VERSION ""

NS_ :

BS_:

BU_: DEBUG BMS DCM FSM PDM DIM GSM INVR INVL CAN_DBG

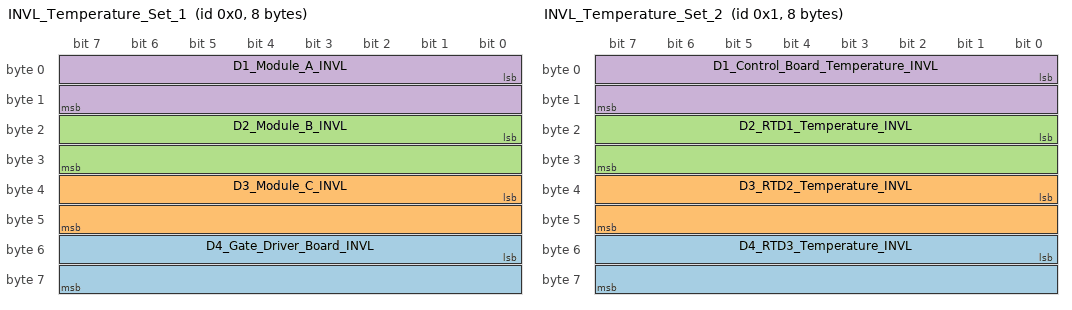
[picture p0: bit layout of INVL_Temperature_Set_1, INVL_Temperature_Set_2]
BO_ 0 INVL_Temperature_Set_1: 8 INVL
SG_ D4_Gate_Driver_Board_INVL : 48|16@1- (0.1,0) [-3276.8|3276.7] "degC" DEBUG
SG_ D3_Module_C_INVL : 32|16@1- (0.1,0) [-3276.8|3276.7] "degC" DEBUG
SG_ D2_Module_B_INVL : 16|16@1- (0.1,0) [-3276.8|3276.7] "degC" DEBUG
SG_ D1_Module_A_INVL : 0|16@1- (0.1,0) [-3276.8|3276.7] "degC" DEBUG

BO_ 1 INVL_Temperature_Set_2: 8 INVL
SG_ D4_RTD3_Temperature_INVL : 48|16@1- (0.1,0) [-3276.8|3276.7] "degC" DEBUG
SG_ D3_RTD2_Temperature_INVL : 32|16@1- (0.1,0) [-3276.8|3276.7] "degC" DEBUG
SG_ D2_RTD1_Temperature_INVL : 16|16@1- (0.1,0) [-3276.8|3276.7] "degC" DEBUG
SG_ D1_Control_Board_Temperature_INVL : 0|16@1- (0.1,0) [-3276.8|3276.7] "degC" DEBUG

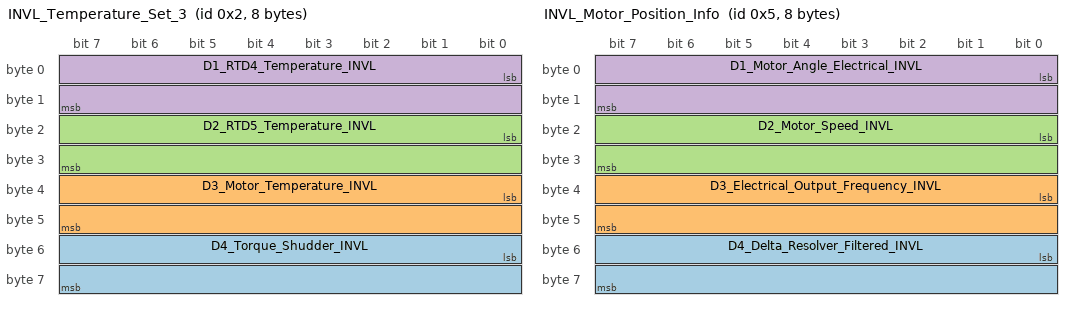
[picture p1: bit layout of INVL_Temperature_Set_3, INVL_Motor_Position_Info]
BO_ 2 INVL_Temperature_Set_3: 8 INVL
SG_ D4_Torque_Shudder_INVL : 48|16@1- (0.1,0) [-3276.8|3276.7] "Nm" DEBUG
SG_ D3_Motor_Temperature_INVL : 32|16@1- (0.1,0) [-3276.8|3276.7] "degC" DEBUG
SG_ D2_RTD5_Temperature_INVL : 16|16@1- (0.1,0) [-3276.8|3276.7] "degC" DEBUG
SG_ D1_RTD4_Temperature_INVL : 0|16@1- (0.1,0) [-3276.8|3276.7] "degC" DEBUG

BO_ 5 INVL_Motor_Position_Info: 8 INVL
SG_ D4_Delta_Resolver_Filtered_INVL : 48|16@1- (0.1,0) [-3276.8|3276.7] "deg" DEBUG
SG_ D3_Electrical_Output_Frequency_INVL : 32|16@1- (0.1,0) [-3276.8|3276.7] "hz" DEBUG
SG_ D2_Motor_Speed_INVL : 16|16@1- (1,0) [-32768|32767] "rpm" DCM
SG_ D1_Motor_Angle_Electrical_INVL : 0|16@1+ (0.1,0) [0|6553.5] "deg" DEBUG

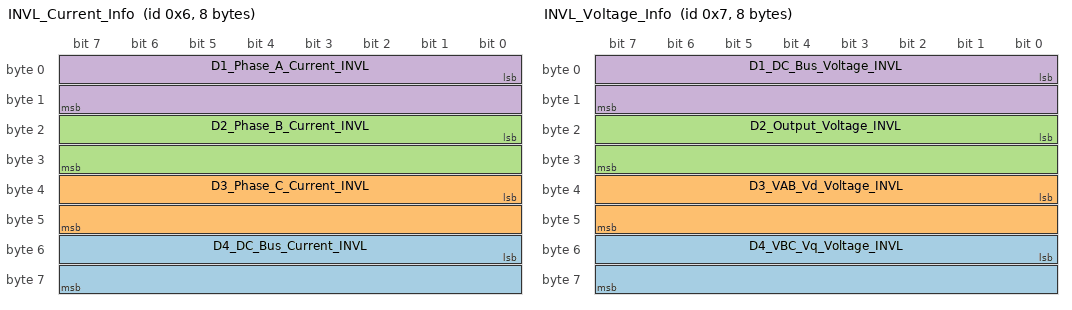
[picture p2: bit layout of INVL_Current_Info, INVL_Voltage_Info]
BO_ 6 INVL_Current_Info: 8 INVL
SG_ D4_DC_Bus_Current_INVL : 48|16@1- (0.1,0) [-3276.8|3276.7] "A" DEBUG
SG_ D3_Phase_C_Current_INVL : 32|16@1- (0.1,0) [-3276.8|3276.7] "A" DEBUG
SG_ D2_Phase_B_Current_INVL : 16|16@1- (0.1,0) [-3276.8|3276.7] "A" DEBUG
SG_ D1_Phase_A_Current_INVL : 0|16@1- (0.1,0) [-3276.8|3276.7] "A" DEBUG

BO_ 7 INVL_Voltage_Info: 8 INVL
SG_ D4_VBC_Vq_Voltage_INVL : 48|16@1- (0.1,0) [-3276.8|3276.7] "V" DEBUG
SG_ D3_VAB_Vd_Voltage_INVL : 32|16@1- (0.1,0) [-3276.8|3276.7] "V" DEBUG
SG_ D2_Output_Voltage_INVL : 16|16@1- (0.1,0) [-3276.8|3276.7] "V" DEBUG
SG_ D1_DC_Bus_Voltage_INVL : 0|16@1- (0.1,0) [-3276.8|3276.7] "V" DEBUG

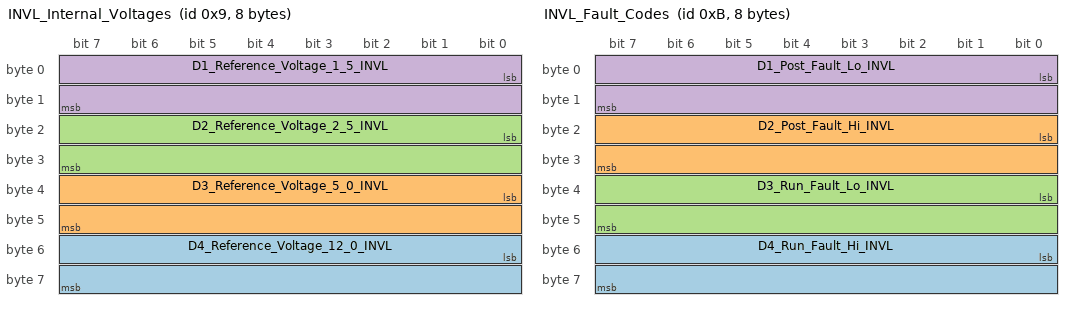
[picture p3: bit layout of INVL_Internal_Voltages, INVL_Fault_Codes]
BO_ 9 INVL_Internal_Voltages: 8 INVL
SG_ D4_Reference_Voltage_12_0_INVL : 48|16@1- (0.01,0) [-327.68|327.67] "V" DEBUG
SG_ D3_Reference_Voltage_5_0_INVL : 32|16@1- (0.01,0) [-327.68|327.67] "V" DEBUG
SG_ D2_Reference_Voltage_2_5_INVL : 16|16@1- (0.01,0) [-327.68|327.67] "V" DEBUG
SG_ D1_Reference_Voltage_1_5_INVL : 0|16@1- (0.01,0) [-327.68|327.67] "V" DEBUG

BO_ 10 INVL_Internal_States: 8 INVL
SG_ D7_Direction_Command_INVL : 56|1@1+ (1,0) [0|1] "" DEBUG
SG_ D6_Inverter_Enable_State_INVL : 48|1@1+ (1,0) [0|1] "" DEBUG
SG_ D3_Relay_3_Status_INVL : 26|1@1+ (1,0) [0|1] "" DEBUG
SG_ D3_Relay_4_Status_INVL : 27|1@1+ (1,0) [0|1] "" DEBUG
SG_ D3_Relay_2_Status_INVL : 25|1@1+ (1,0) [0|1] "" DEBUG
SG_ D4_Inverter_Run_Mode_INVL : 32|1@1+ (1,0) [0|1] "" DEBUG
SG_ D5_Inverter_Command_Mode_INVL : 40|1@1+ (1,0) [0|1] "" DEBUG
SG_ D3_Relay_1_Status_INVL : 24|1@1+ (1,0) [0|1] "" DEBUG
SG_ D2_Inverter_State_INVL : 16|8@1+ (1,0) [0|255] "" DEBUG
SG_ D1_VSM_State_INVL : 0|8@1+ (1,0) [0|15] "" DCM
SG_ D6_Inverter_Enable_Lockout_INVL : 55|1@1+ (1,0) [0|1] "" DEBUG
SG_ D4_Inverter_Discharge_State_INVL : 37|3@1+ (1,0) [0|7] "" DEBUG
SG_ D3_Relay_5_Status_INVL : 28|1@1+ (1,0) [0|1] "" DEBUG
SG_ D3_Relay_6_Status_INVL : 29|1@1+ (1,0) [0|1] "" DEBUG
SG_ D7_BMS_Active_INVL : 57|1@1+ (1,0) [0|1] "" DEBUG
SG_ D7_BMS_Torque_Limiting_INVL : 58|1@1+ (1,0) [0|1] "" DEBUG
SG_ D7_Max_Speed_Limiting_INVL : 59|1@1+ (1,0) [0|1] "" DEBUG
SG_ D7_Low_Speed_Limiting_INVL : 61|1@1+ (1,0) [0|1] "" DEBUG
SG_ D5_Rolling_Counter_INVL : 44|4@1+ (1,0) [0|15] "" DEBUG
SG_ D1_PWM_Frequency_INVL : 8|8@1+ (1,0) [0|255] "kHz" DEBUG
SG_ D6_Start_Mode_Active_INVL : 54|1@1+ (1,0) [0|1] "" DEBUG

BO_ 11 INVL_Fault_Codes: 8 INVL
SG_ D4_Run_Fault_Hi_INVL : 48|16@1+ (1,0) [0|65535] "" DEBUG
SG_ D2_Post_Fault_Hi_INVL : 16|16@1+ (1,0) [0|65535] "" DEBUG
SG_ D3_Run_Fault_Lo_INVL : 32|16@1+ (1,0) [0|65535] "" DEBUG
SG_ D1_Post_Fault_Lo_INVL : 0|16@1+ (1,0) [0|65535] "" DEBUG

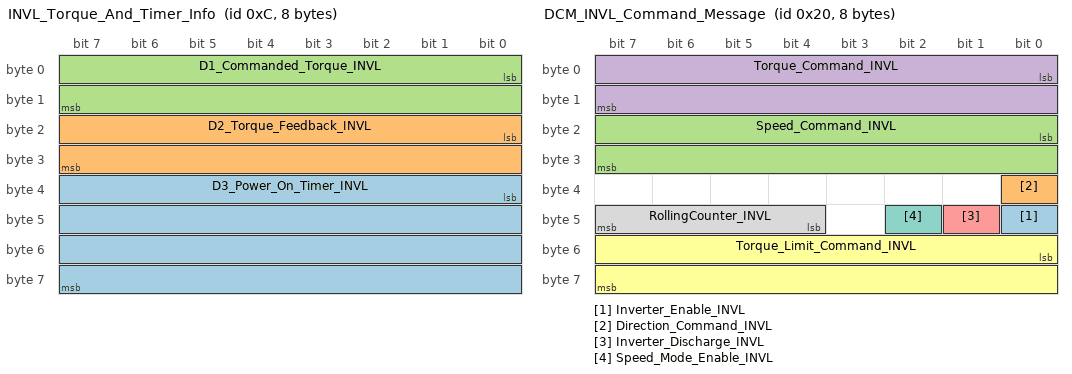
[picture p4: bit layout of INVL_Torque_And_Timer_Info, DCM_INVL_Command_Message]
BO_ 12 INVL_Torque_And_Timer_Info: 8 INVL
SG_ D3_Power_On_Timer_INVL : 32|32@1+ (0.003,0) [0|12884800] "Sec" DEBUG
SG_ D2_Torque_Feedback_INVL : 16|16@1- (0.1,0) [-3276.8|3276.7] "Nm" DEBUG
SG_ D1_Commanded_Torque_INVL : 0|16@1- (0.1,0) [-3276.8|3276.7] "Nm" DEBUG

BO_ 32 DCM_INVL_Command_Message: 8 DCM
SG_ Inverter_Enable_INVL : 40|1@1+ (1,0) [0|1] "Bit" INVL
SG_ Direction_Command_INVL : 32|1@1+ (1,0) [0|1] "Bit" INVL
SG_ Speed_Command_INVL : 16|16@1- (1,0) [-32768|32767] "rpm" INVL
SG_ Torque_Command_INVL : 0|16@1- (0.1,0) [-3276.8|3276.7] "Nm" INVL,FSM
SG_ Inverter_Discharge_INVL : 41|1@1+ (1,0) [0|1] "Bit" INVL
SG_ Torque_Limit_Command_INVL : 48|16@1- (0.1,0) [-3276.8|3276.7] "Nm" INVL
SG_ Speed_Mode_Enable_INVL : 42|1@1+ (1,0) [0|1] "Bit" INVL
SG_ RollingCounter_INVL : 44|4@1+ (1,0) [0|15] "Bits" INVL

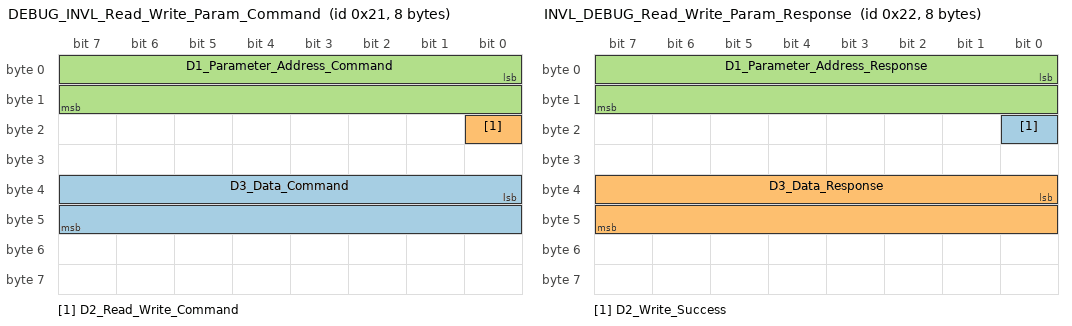
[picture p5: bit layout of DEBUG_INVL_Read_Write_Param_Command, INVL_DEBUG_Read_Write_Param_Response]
BO_ 33 DEBUG_INVL_Read_Write_Param_Command: 8 DEBUG
SG_ D3_Data_Command : 32|16@1- (1,0) [-32768|32767] "" INVL
SG_ D2_Read_Write_Command : 16|1@1+ (1,0) [0|1] "" INVL
SG_ D1_Parameter_Address_Command : 0|16@1+ (1,0) [0|65535] "" INVL

BO_ 34 INVL_DEBUG_Read_Write_Param_Response: 8 INVL
SG_ D2_Write_Success : 16|1@1+ (1,0) [0|1] "" DEBUG
SG_ D3_Data_Response : 32|16@1- (1,0) [-32768|32767] "" DEBUG
SG_ D1_Parameter_Address_Response : 0|16@1+ (1,0) [0|65535] "" DEBUG

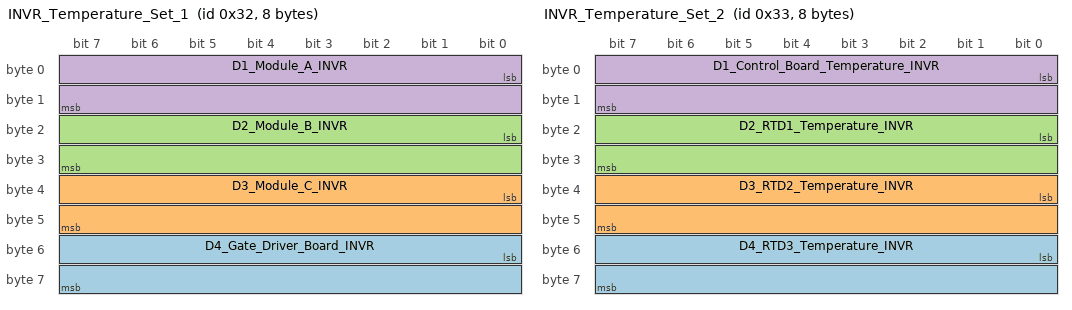
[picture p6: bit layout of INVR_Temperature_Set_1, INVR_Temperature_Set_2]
BO_ 50 INVR_Temperature_Set_1: 8 INVR
SG_ D4_Gate_Driver_Board_INVR : 48|16@1- (0.1,0) [-3276.8|3276.7] "degC" DEBUG
SG_ D3_Module_C_INVR : 32|16@1- (0.1,0) [-3276.8|3276.7] "degC" DEBUG
SG_ D2_Module_B_INVR : 16|16@1- (0.1,0) [-3276.8|3276.7] "degC" DEBUG
SG_ D1_Module_A_INVR : 0|16@1- (0.1,0) [-3276.8|3276.7] "degC" DEBUG

BO_ 51 INVR_Temperature_Set_2: 8 INVR
SG_ D4_RTD3_Temperature_INVR : 48|16@1- (0.1,0) [-3276.8|3276.7] "degC" DEBUG
SG_ D3_RTD2_Temperature_INVR : 32|16@1- (0.1,0) [-3276.8|3276.7] "degC" DEBUG
SG_ D2_RTD1_Temperature_INVR : 16|16@1- (0.1,0) [-3276.8|3276.7] "degC" DEBUG
SG_ D1_Control_Board_Temperature_INVR : 0|16@1- (0.1,0) [-3276.8|3276.7] "degC" DEBUG

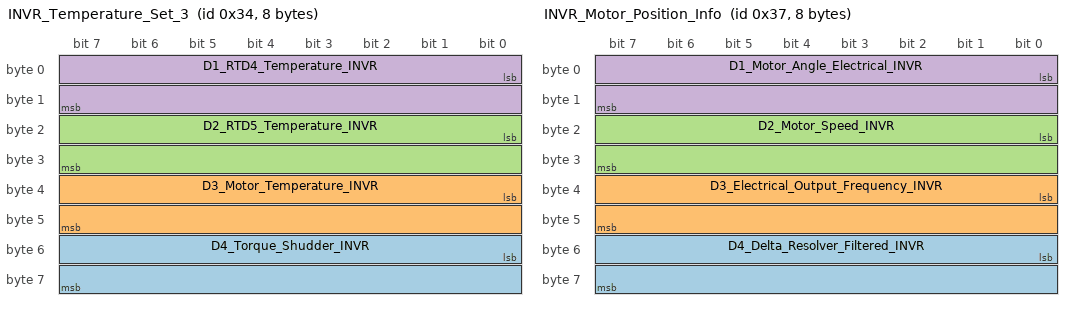
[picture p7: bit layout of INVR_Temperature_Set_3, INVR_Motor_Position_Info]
BO_ 52 INVR_Temperature_Set_3: 8 INVR
SG_ D4_Torque_Shudder_INVR : 48|16@1- (0.1,0) [-3276.8|3276.7] "Nm" DEBUG
SG_ D3_Motor_Temperature_INVR : 32|16@1- (0.1,0) [-3276.8|3276.7] "degC" DEBUG
SG_ D2_RTD5_Temperature_INVR : 16|16@1- (0.1,0) [-3276.8|3276.7] "degC" DEBUG
SG_ D1_RTD4_Temperature_INVR : 0|16@1- (0.1,0) [-3276.8|3276.7] "degC" DEBUG

BO_ 55 INVR_Motor_Position_Info: 8 INVR
SG_ D4_Delta_Resolver_Filtered_INVR : 48|16@1- (0.1,0) [-3276.8|3276.7] "deg" DEBUG
SG_ D3_Electrical_Output_Frequency_INVR : 32|16@1- (0.1,0) [-3276.8|3276.7] "hz" DEBUG
SG_ D2_Motor_Speed_INVR : 16|16@1- (1,0) [-32768|32767] "rpm" DCM
SG_ D1_Motor_Angle_Electrical_INVR : 0|16@1+ (0.1,0) [0|6553.5] "deg" DEBUG

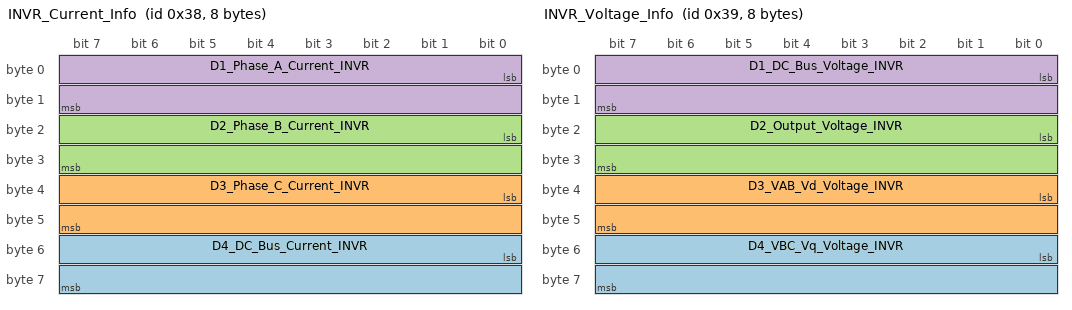
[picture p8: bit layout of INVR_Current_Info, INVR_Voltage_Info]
BO_ 56 INVR_Current_Info: 8 INVR
SG_ D4_DC_Bus_Current_INVR : 48|16@1- (0.1,0) [-3276.8|3276.7] "A" DEBUG
SG_ D3_Phase_C_Current_INVR : 32|16@1- (0.1,0) [-3276.8|3276.7] "A" DEBUG
SG_ D2_Phase_B_Current_INVR : 16|16@1- (0.1,0) [-3276.8|3276.7] "A" DEBUG
SG_ D1_Phase_A_Current_INVR : 0|16@1- (0.1,0) [-3276.8|3276.7] "A" DEBUG

BO_ 57 INVR_Voltage_Info: 8 INVR
SG_ D4_VBC_Vq_Voltage_INVR : 48|16@1- (0.1,0) [-3276.8|3276.7] "V" DEBUG
SG_ D3_VAB_Vd_Voltage_INVR : 32|16@1- (0.1,0) [-3276.8|3276.7] "V" DEBUG
SG_ D2_Output_Voltage_INVR : 16|16@1- (0.1,0) [-3276.8|3276.7] "V" DEBUG
SG_ D1_DC_Bus_Voltage_INVR : 0|16@1- (0.1,0) [-3276.8|3276.7] "V" DEBUG

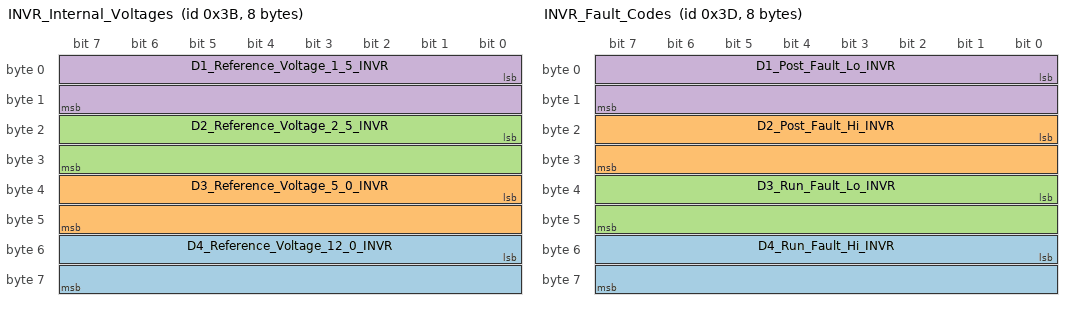
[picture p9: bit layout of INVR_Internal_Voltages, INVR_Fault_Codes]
BO_ 59 INVR_Internal_Voltages: 8 INVR
SG_ D4_Reference_Voltage_12_0_INVR : 48|16@1- (0.01,0) [-327.68|327.67] "V" DEBUG
SG_ D3_Reference_Voltage_5_0_INVR : 32|16@1- (0.01,0) [-327.68|327.67] "V" DEBUG
SG_ D2_Reference_Voltage_2_5_INVR : 16|16@1- (0.01,0) [-327.68|327.67] "V" DEBUG
SG_ D1_Reference_Voltage_1_5_INVR : 0|16@1- (0.01,0) [-327.68|327.67] "V" DEBUG

BO_ 60 INVR_Internal_States: 8 INVR
SG_ D7_Direction_Command_INVR : 56|1@1+ (1,0) [0|1] "" DEBUG
SG_ D6_Inverter_Enable_State_INVR : 48|1@1+ (1,0) [0|1] "" DEBUG
SG_ D3_Relay_3_Status_INVR : 26|1@1+ (1,0) [0|1] "" DEBUG
SG_ D3_Relay_4_Status_INVR : 27|1@1+ (1,0) [0|1] "" DEBUG
SG_ D3_Relay_2_Status_INVR : 25|1@1+ (1,0) [0|1] "" DEBUG
SG_ D4_Inverter_Run_Mode_INVR : 32|1@1+ (1,0) [0|1] "" DEBUG
SG_ D5_Inverter_Command_Mode_INVR : 40|1@1+ (1,0) [0|1] "" DEBUG
SG_ D3_Relay_1_Status_INVR : 24|1@1+ (1,0) [0|1] "" DEBUG
SG_ D2_Inverter_State_INVR : 16|8@1+ (1,0) [0|255] "" DEBUG
SG_ D1_VSM_State_INVR : 0|8@1+ (1,0) [0|15] "" DCM
SG_ D6_Inverter_Enable_Lockout_INVR : 55|1@1+ (1,0) [0|1] "" DEBUG
SG_ D4_Inverter_Discharge_State_INVR : 37|3@1+ (1,0) [0|7] "" DEBUG
SG_ D3_Relay_5_Status_INVR : 28|1@1+ (1,0) [0|1] "" DEBUG
SG_ D3_Relay_6_Status_INVR : 29|1@1+ (1,0) [0|1] "" DEBUG
SG_ D7_BMS_Active_INVR : 57|1@1+ (1,0) [0|1] "" DEBUG
SG_ D7_BMS_Torque_Limiting_INVR : 58|1@1+ (1,0) [0|1] "" DEBUG
SG_ D7_Max_Speed_Limiting_INVR : 59|1@1+ (1,0) [0|1] "" DEBUG
SG_ D7_Low_Speed_Limiting_INVR : 61|1@1+ (1,0) [0|1] "" DEBUG
SG_ D5_Rolling_Counter_INVR : 44|4@1+ (1,0) [0|15] "" DEBUG
SG_ D1_PWM_Frequency_INVR : 8|8@1+ (1,0) [0|255] "kHz" DEBUG
SG_ D6_Start_Mode_Active_INVR : 54|1@1+ (1,0) [0|1] "" DEBUG

BO_ 61 INVR_Fault_Codes: 8 INVR
SG_ D4_Run_Fault_Hi_INVR : 48|16@1+ (1,0) [0|65535] "" DEBUG
SG_ D2_Post_Fault_Hi_INVR : 16|16@1+ (1,0) [0|65535] "" DEBUG
SG_ D3_Run_Fault_Lo_INVR : 32|16@1+ (1,0) [0|65535] "" DEBUG
SG_ D1_Post_Fault_Lo_INVR : 0|16@1+ (1,0) [0|65535] "" DEBUG

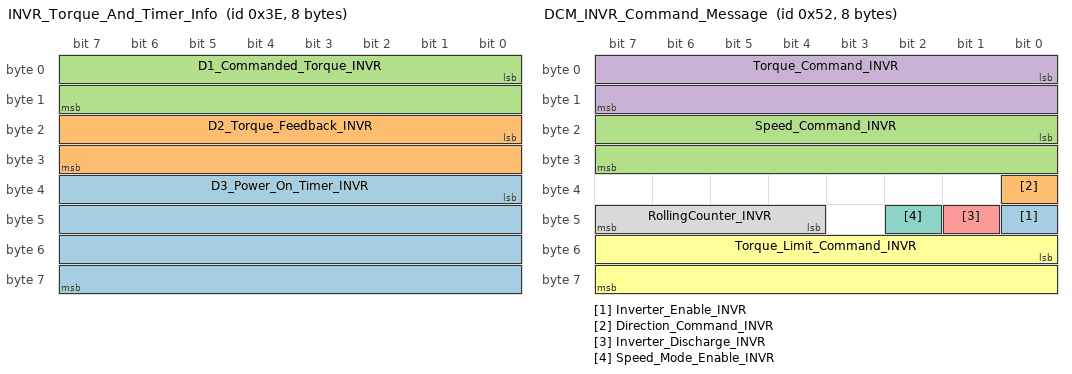
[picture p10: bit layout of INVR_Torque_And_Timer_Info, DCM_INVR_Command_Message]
BO_ 62 INVR_Torque_And_Timer_Info: 8 INVR
SG_ D3_Power_On_Timer_INVR : 32|32@1+ (0.003,0) [0|12884800] "Sec" DEBUG
SG_ D2_Torque_Feedback_INVR : 16|16@1- (0.1,0) [-3276.8|3276.7] "Nm" DEBUG
SG_ D1_Commanded_Torque_INVR : 0|16@1- (0.1,0) [-3276.8|3276.7] "Nm" DEBUG

BO_ 82 DCM_INVR_Command_Message: 8 DCM
SG_ Inverter_Enable_INVR : 40|1@1+ (1,0) [0|1] "Bit" INVR
SG_ Direction_Command_INVR : 32|1@1+ (1,0) [0|1] "Bit" INVR
SG_ Speed_Command_INVR : 16|16@1- (1,0) [-32768|32767] "rpm" INVR
SG_ Torque_Command_INVR : 0|16@1- (0.1,0) [-3276.8|3276.7] "Nm" INVR,FSM
SG_ Inverter_Discharge_INVR : 41|1@1+ (1,0) [0|1] "Bit" INVR
SG_ Torque_Limit_Command_INVR : 48|16@1- (0.1,0) [-3276.8|3276.7] "Nm" INVR
SG_ Speed_Mode_Enable_INVR : 42|1@1+ (1,0) [0|1] "Bit" INVR
SG_ RollingCounter_INVR : 44|4@1+ (1,0) [0|15] "Bits" INVR

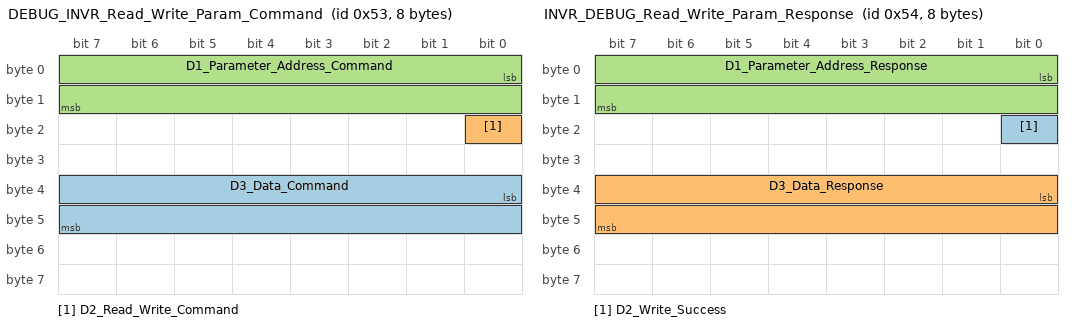
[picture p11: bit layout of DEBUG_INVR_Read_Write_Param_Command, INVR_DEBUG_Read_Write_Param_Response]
BO_ 83 DEBUG_INVR_Read_Write_Param_Command: 8 DEBUG
SG_ D3_Data_Command : 32|16@1- (1,0) [-32768|32767] "" INVR
SG_ D2_Read_Write_Command : 16|1@1+ (1,0) [0|1] "" INVR
SG_ D1_Parameter_Address_Command : 0|16@1+ (1,0) [0|65535] "" INVR

BO_ 84 INVR_DEBUG_Read_Write_Param_Response: 8 INVR
SG_ D2_Write_Success : 16|1@1+ (1,0) [0|1] "" DEBUG
SG_ D3_Data_Response : 32|16@1- (1,0) [-32768|32767] "" DEBUG
SG_ D1_Parameter_Address_Response : 0|16@1+ (1,0) [0|65535] "" DEBUG

BO_ 13 FSM_PEDAL_POSITION: 4 FSM
SG_ Mapped_Pedal_Percentage: 0|32@1+ (1,0) [0|100] "%" DCM

BO_ 90 FSM_Torque_Limiting : 4 FSM
SG_ FSM_Torque_Limit : 0|32@1+ (1,0) [0.0|150.0] "Nm" DCM

BO_ 100 BMS_VITALS: 1 BMS
SG_ HEARTBEAT : 0|1@1+ (1,0) [0|1] "" FSM,DCM,PDM,DIM,GSM

BO_ 101 BMS_CAN_FIFO_OVERFLOW: 8 BMS
SG_ tx_overflow_count : 0|32@1+ (1,0) [0|4294967295] "" DEBUG
SG_ rx_overflow_count : 32|32@1+ (1,0) [0|4294967295] "" DEBUG

BO_ 102 BMS_STARTUP: 0 BMS

BO_ 103 BMS_WATCHDOG_TIMEOUT : 8 BMS
SG_ TASK_NAME : 0|64@1+ (1,0) [0|0] "" DEBUG

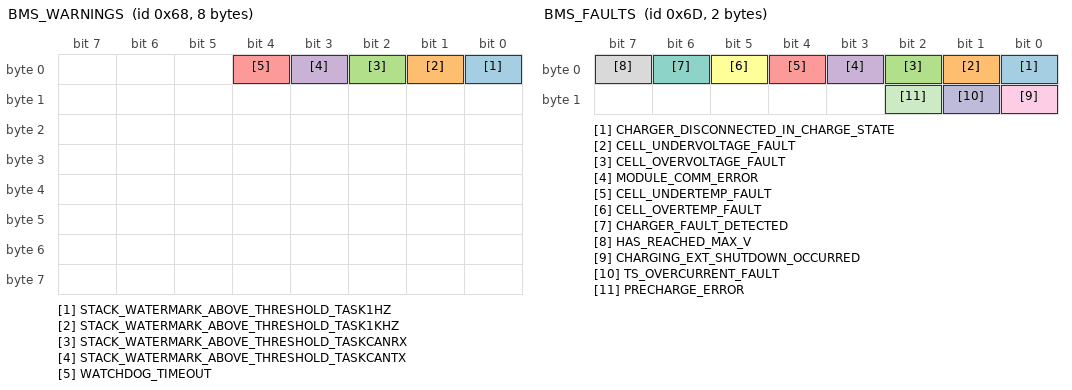
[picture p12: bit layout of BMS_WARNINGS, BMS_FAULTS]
BO_ 104 BMS_WARNINGS: 8 BMS
SG_ STACK_WATERMARK_ABOVE_THRESHOLD_TASK1HZ : 0|1@1+ (1,0) [0|1] "" DIM
SG_ STACK_WATERMARK_ABOVE_THRESHOLD_TASK1KHZ : 1|1@1+ (1,0) [0|1] "" DIM
SG_ STACK_WATERMARK_ABOVE_THRESHOLD_TASKCANRX : 2|1@1+ (1,0) [0|1] "" DIM
SG_ STACK_WATERMARK_ABOVE_THRESHOLD_TASKCANTX : 3|1@1+ (1,0) [0|1] "" DIM
SG_ WATCHDOG_TIMEOUT : 4|1@1+ (1,0) [0|1] "" DIM

BO_ 105 BMS_IMD: 8 BMS
SG_ Condition M : 0|3@1+ (1,0) [0|6] "" DEBUG
SG_ Seconds_Since_Power_On : 3|16@1+ (1,0) [0|255] "Seconds" DEBUG
SG_ Valid_Duty_Cycle : 19|1@1+ (1,0) [0|1] "" DEBUG
SG_ Insulation_Measurement_DCP_10Hz m1 : 20|16@1+ (1,0) [0|65535] "kOhm" DEBUG
SG_ Insulation_Measurement_DCP_20Hz m2 : 20|16@1+ (1,0) [0|65535] "kOhm" DEBUG
SG_ Speed_Start_Status_30Hz m3 : 20|16@1+ (1,0) [0|65535] "" DEBUG
SG_ OK_HS : 36|1@1+ (1,0) [0|1] "" DIM

BO_ 106 BMS_IMD_PWM_OUTPUT : 8 BMS
SG_ Duty_Cycle : 0|32@1- (1,0) [0|1E2] "%" DEBUG
SG_ Frequency : 32|32@1- (1,0) [0|1E4] "Hz" DEBUG

BO_ 107 BMS_STATE_MACHINE : 1 BMS
SG_ State : 0|8@1+ (1,0) [0|255] "" DCM,DIM

BO_ 108 BMS_STATE_OF_CHARGE: 4 BMS
SG_ State_Of_Charge : 0|32@1- (1,0) [0|1E2] "%" DIM

BO_ 109 BMS_FAULTS: 2 BMS
SG_ CHARGER_DISCONNECTED_IN_CHARGE_STATE : 0|1@1+ (1,0) [0|1] "" DEBUG
SG_ CELL_UNDERVOLTAGE_FAULT : 1|1@1+ (1,0) [0|1] "" DEBUG
SG_ CELL_OVERVOLTAGE_FAULT : 2|1@1+ (1,0) [0|1] "" DEBUG
SG_ MODULE_COMM_ERROR: 3|1@1+ (1,0) [0|1] "" DEBUG
SG_ CELL_UNDERTEMP_FAULT: 4|1@1+ (1,0) [0|1] "" DEBUG
SG_ CELL_OVERTEMP_FAULT: 5|1@1+ (1,0) [0|1] "" DEBUG
SG_ CHARGER_FAULT_DETECTED : 6|1@1+ (1,0) [0|1] "" DEBUG
SG_ HAS_REACHED_MAX_V : 7|1@1+ (1,0) [0|1] "" DEBUG
SG_ CHARGING_EXT_SHUTDOWN_OCCURRED : 8|1@1+ (1,0) [0|1] "" DEBUG
SG_ TS_OVERCURRENT_FAULT : 9|1@1+ (1,0) [0|1] "" DEBUG
SG_ PRECHARGE_ERROR : 10|1@1+ (1,0) [0|1] "" DEBUG

BO_ 110 BMS_CHARGER: 1 BMS
SG_ Is_Connected : 0|1@1+ (1,0) [0|1] "" DEBUG
SG_ IS_CHARGING_COMPLETE : 1|1@1+ (1,0) [0|1] "" DEBUG

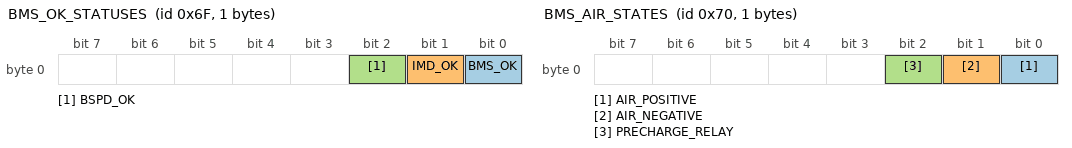
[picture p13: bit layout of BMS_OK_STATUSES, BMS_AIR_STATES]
BO_ 111 BMS_OK_STATUSES: 1 BMS
SG_ BMS_OK : 0|1@1+ (1,0) [0|1] "" DIM
SG_ IMD_OK : 1|1@1+ (1,0) [0|1] "" DIM
SG_ BSPD_OK : 2|1@1+ (1,0) [0|1] "" DIM

BO_ 112 BMS_AIR_STATES: 1 BMS
SG_ AIR_POSITIVE : 0|1@1+ (1,0) [0|1] "" FSM,DCM,PDM
SG_ AIR_NEGATIVE : 1|1@1+ (1,0) [0|1] "" FSM,DCM,PDM
SG_ PRECHARGE_RELAY: 2|1@1+ (1,0) [0|1] "" DEBUG

BO_ 113 BMS_MOTOR_SHUTDOWN_ERRORS: 8 BMS
SG_ DUMMY_MOTOR_SHUTDOWN : 0|1@1+ (1,0) [0|1] "" DCM

BO_ 114 BMS_CELL_TEMPERATURES: 8 BMS
SG_ MIN_CELL_TEMPERATURE: 0|32@1+ (1,0) [0|100] "degC" DEBUG
SG_ MAX_CELL_TEMPERATURE: 32|32@1+ (1,0) [0|100] "degC" DEBUG

BO_ 115 BMS_CELL_VOLTAGES: 8 BMS
SG_ MIN_CELL_VOLTAGE : 0|32@1+ (1,0) [0|5] "" DEBUG
SG_ MAX_CELL_VOLTAGE : 32|32@1+ (1,0) [0|5] "" DEBUG

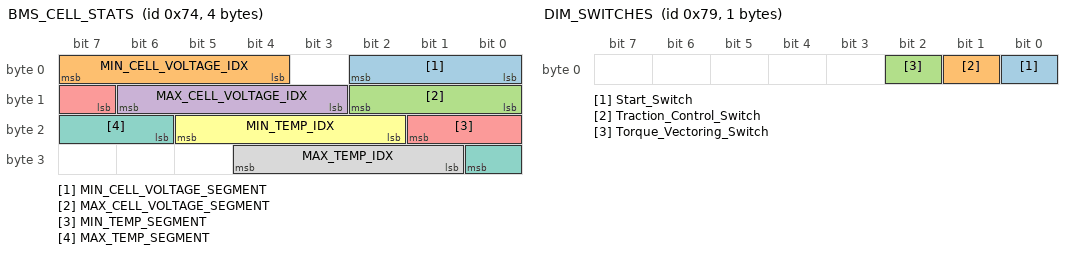
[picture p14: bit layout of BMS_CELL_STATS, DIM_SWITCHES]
BO_ 116 BMS_CELL_STATS: 4 BMS
SG_ MIN_CELL_VOLTAGE_SEGMENT : 0|3@1+ (1,0) [0|7] "" DEBUG
SG_ MIN_CELL_VOLTAGE_IDX : 4|4@1+ (1,0) [0|15] "" DEBUG
SG_ MAX_CELL_VOLTAGE_SEGMENT : 8|3@1+ (1,0) [0|7] "" DEBUG
SG_ MAX_CELL_VOLTAGE_IDX : 11|4@1+ (1,0) [0|7] "" DEBUG
SG_ MIN_TEMP_SEGMENT : 15|3@1+ (1,0) [0|7] "" DEBUG
SG_ MIN_TEMP_IDX : 18|4@1+ (1,0) [0|15] "" DEBUG
SG_ MAX_TEMP_SEGMENT : 22|3@1+ (1,0) [0|7] "" DEBUG
SG_ MAX_TEMP_IDX : 25|4@1+ (1,0) [0|7] "" DEBUG

BO_ 117 BMS_TRACTIVE_SYSTEM: 8 BMS
SG_ TS_VOLTAGE : 0|32@1+ (1,0) [0|600] "" DEBUG
SG_ TS_CURRENT : 32|32@1+ (1,0) [-300|300] "" DEBUG

BO_ 118 BMS_PACK_VOLTAGE: 4 BMS
SG_ PACK_VOLTAGE : 0|32@1+ (1,0) [0|600] "" DEBUG

BO_ 120 BMS_AVAILABLE_POWER: 4 BMS
SG_ AVAILABLE_POWER : 0|32@1+ (1,0) [0|100000] "W" DCM

BO_ 121 DIM_SWITCHES: 1 DIM
SG_ Start_Switch : 0|1@1+ (1,0) [0|1] "" DCM
SG_ Traction_Control_Switch : 1|1@1+ (1,0) [0|1] "" DCM
SG_ Torque_Vectoring_Switch : 2|1@1+ (1,0) [0|1] "" DCM

BO_ 151 FSM_APPS: 8 FSM
SG_ Papps_Mapped_Pedal_Percentage : 0|32@1+ (1,0) [0|100] "%" DEBUG
SG_ Sapps_Mapped_Pedal_Percentage : 32|32@1+ (1,0) [0|100] "%" DEBUG

BO_ 200 DCM_VITALS: 1 DCM
SG_ HEARTBEAT : 0|1@1+ (1,0) [0|1] "" BMS

BO_ 201 DCM_CAN_FIFO_OVERFLOW: 8 DCM
SG_ tx_overflow_count : 0|32@1+ (1,0) [0|4294967295] "" DEBUG
SG_ rx_overflow_count : 32|32@1+ (1,0) [0|4294967295] "" DEBUG

BO_ 202 DCM_STARTUP: 0 DCM

BO_ 203 DCM_WATCHDOG_TIMEOUT : 8 DCM
SG_ TASK_NAME : 0|64@1+ (1,0) [0|0] "" DEBUG

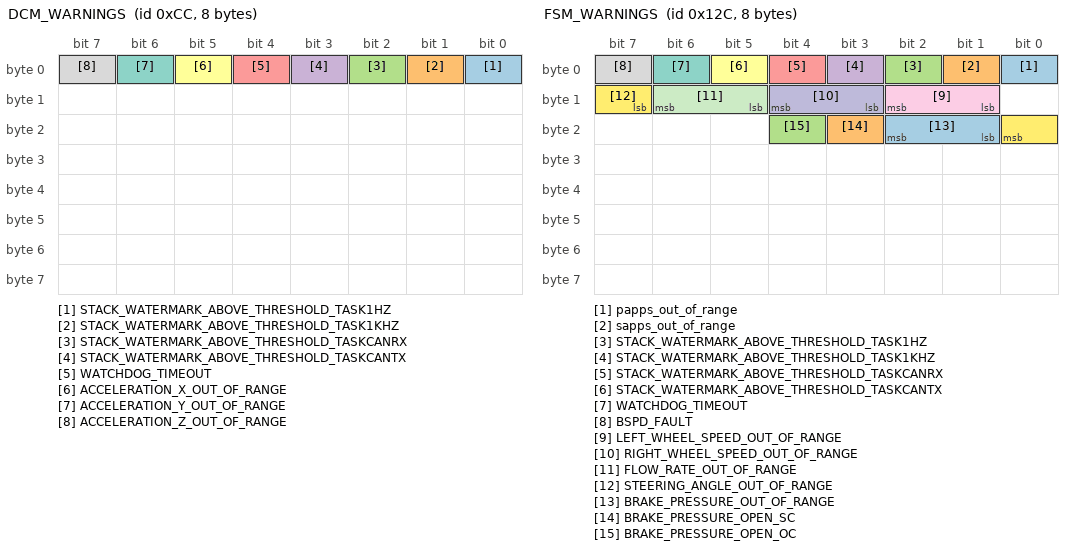
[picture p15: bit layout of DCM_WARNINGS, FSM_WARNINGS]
BO_ 204 DCM_WARNINGS: 8 DCM
SG_ STACK_WATERMARK_ABOVE_THRESHOLD_TASK1HZ : 0|1@1+ (1,0) [0|1] "" DEBUG
SG_ STACK_WATERMARK_ABOVE_THRESHOLD_TASK1KHZ : 1|1@1+ (1,0) [0|1] "" DEBUG
SG_ STACK_WATERMARK_ABOVE_THRESHOLD_TASKCANRX : 2|1@1+ (1,0) [0|1] "" DEBUG
SG_ STACK_WATERMARK_ABOVE_THRESHOLD_TASKCANTX : 3|1@1+ (1,0) [0|1] "" DEBUG
SG_ WATCHDOG_TIMEOUT : 4|1@1+ (1,0) [0|1] "" DEBUG
SG_ ACCELERATION_X_OUT_OF_RANGE : 5|1@1+ (1,0) [0|1] "" DEBUG
SG_ ACCELERATION_Y_OUT_OF_RANGE : 6|1@1+ (1,0) [0|1] "" DEBUG
SG_ ACCELERATION_Z_OUT_OF_RANGE : 7|1@1+ (1,0) [0|1] "" DEBUG

BO_ 205 DCM_STATE_MACHINE : 1 DCM
SG_ State : 0|8@1+ (1,0) [0|255] "" DEBUG

BO_ 206 DCM_TORQUE_REQUEST : 4 DCM
SG_ Torque_Request : 0|32@1+ (1,0) [-3.4E038|3.4E038] "" LOGGER

BO_ 207 DCM_AIR_SHUTDOWN_ERRORS: 1 DCM
SG_ MISSING_HEARTBEAT: 0|1@1+ (1,0) [0|1] "" DEBUG

BO_ 208 DCM_MOTOR_SHUTDOWN_ERRORS: 8 DCM
SG_ DUMMY_MOTOR_SHUTDOWN : 0|1@1+ (1,0) [0|1] "" DCM

BO_ 212 DCM_INVERTER_SWITCHES: 1 DCM
SG_ Right_Inverter_Switch : 0|1@1+ (1,0) [0|1] "" DEBUG
SG_ Left_Inverter_Switch : 1|1@1+ (1,0) [0|1] "" DEBUG

BO_ 300 FSM_WARNINGS: 8 FSM
SG_ papps_out_of_range : 0|1@1+ (1,0) [0|1] "" DEBUG
SG_ sapps_out_of_range : 1|1@1+ (1,0) [0|1] "" DEBUG
SG_ STACK_WATERMARK_ABOVE_THRESHOLD_TASK1HZ : 2|1@1+ (1,0) [0|1] "" DEBUG
SG_ STACK_WATERMARK_ABOVE_THRESHOLD_TASK1KHZ : 3|1@1+ (1,0) [0|1] "" DEBUG
SG_ STACK_WATERMARK_ABOVE_THRESHOLD_TASKCANRX : 4|1@1+ (1,0) [0|1] "" DEBUG
SG_ STACK_WATERMARK_ABOVE_THRESHOLD_TASKCANTX : 5|1@1+ (1,0) [0|1] "" DEBUG
SG_ WATCHDOG_TIMEOUT : 6|1@1+ (1,0) [0|1] "" DEBUG
SG_ BSPD_FAULT : 7|1@1+ (1,0) [0|1] "" DIM
SG_ LEFT_WHEEL_SPEED_OUT_OF_RANGE: 9|2@1+ (1,0) [0|2] "" DEBUG
SG_ RIGHT_WHEEL_SPEED_OUT_OF_RANGE: 11|2@1+ (1,0) [0|2] ""  DEBUG
SG_ FLOW_RATE_OUT_OF_RANGE: 13|2@1+ (1,0) [0|2] "" DEBUG
SG_ STEERING_ANGLE_OUT_OF_RANGE: 15|2@1+ (1,0) [0|2] "" DEBUG
SG_ BRAKE_PRESSURE_OUT_OF_RANGE: 17|2@1+ (1,0) [0|2] "" DEBUG
SG_ BRAKE_PRESSURE_OPEN_SC: 19|1@1+ (1,0) [0|1] "" DEBUG
SG_ BRAKE_PRESSURE_OPEN_OC: 20|1@1+ (1,0) [0|1] "" DEBUG

BO_ 301 FSM_VITALS: 1 FSM
SG_ HEARTBEAT : 0|1@1+ (1,0) [0|1] "" BMS

BO_ 302 FSM_CAN_FIFO_OVERFLOW: 8 FSM
SG_ tx_overflow_count : 0|32@1+ (1,0) [0|1] "" DEBUG
SG_ rx_overflow_count : 32|32@1+ (1,0) [0|1] "" DEBUG

BO_ 303 FSM_STARTUP: 0 FSM

BO_ 304 FSM_WATCHDOG_TIMEOUT : 8 FSM
SG_ TASK_NAME : 0|64@1+ (1,0) [0|0] "" DEBUG

BO_ 305 FSM_STATE_MACHINE : 1 FSM
SG_ State : 0|8@1+ (1,0) [0|255] "" DEBUG

BO_ 306 FSM_AIR_SHUTDOWN: 0 FSM

BO_ 307 FSM_FLOW_METER: 8 FSM
SG_ FLOW_RATE: 0|32@1+ (1,0) [0|100] "L/min" DEBUG

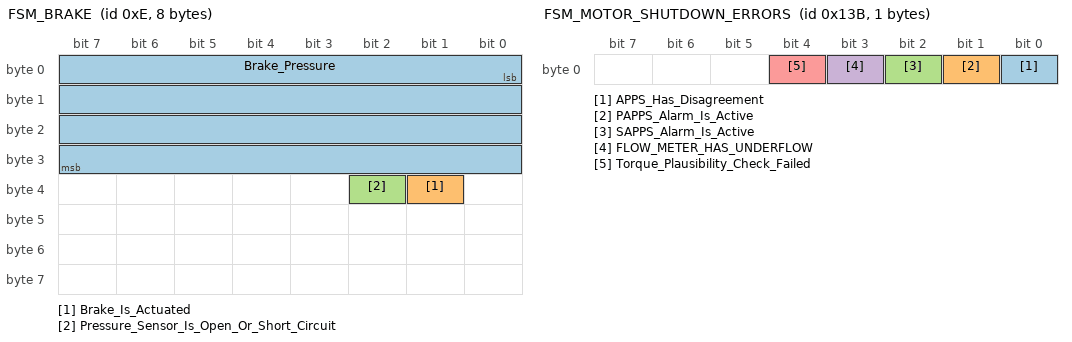
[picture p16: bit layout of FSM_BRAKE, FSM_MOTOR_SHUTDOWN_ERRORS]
BO_ 14 FSM_BRAKE: 8 FSM
SG_ Brake_Pressure: 0|32@1+ (1,0) [0|2500] "psi" DEBUG
SG_ Brake_Is_Actuated: 33|1@1+ (1,0) [0|1] "" DCM
SG_ Pressure_Sensor_Is_Open_Or_Short_Circuit: 34|1@1+ (1,0) [0|1] "" DEBUG

BO_ 310 FSM_AIR_SHUTDOWN_ERRORS: 1 FSM
SG_ MISSING_HEARTBEAT : 0|1@1+ (1,0) [0|1] "" DEBUG

BO_ 315 FSM_MOTOR_SHUTDOWN_ERRORS: 1 FSM
SG_ APPS_Has_Disagreement : 0|1@1+ (1,0) [0|1] "" DCM
SG_ PAPPS_Alarm_Is_Active : 1|1@1+ (1,0) [0|1] "" DCM
SG_ SAPPS_Alarm_Is_Active : 2|1@1+ (1,0) [0|1] "" DCM
SG_ FLOW_METER_HAS_UNDERFLOW : 3|1@1+ (1,0) [0|1] "" DCM
SG_ Torque_Plausibility_Check_Failed : 4|1@1+ (1,0) [0|1] "" DCM

BO_ 317 FSM_WHEEL_SPEED_SENSOR: 8 FSM
SG_ Left_Wheel_Speed : 0|32@1+ (1,0) [0|150] "km/h" DCM
SG_ Right_Wheel_Speed : 32|32@1+ (1,0) [0|150] "km/h" DCM

BO_ 318 FSM_STEERING_ANGLE_SENSOR: 4 FSM
SG_ Steering_Angle : 0|32@1+ (1,0) [-110|110] "deg" DCM

BO_ 319 APPS_DBUG: 4 FSM
SG_ SAPPS: 0|16@1+ (1,0) [0|65535] "" DEBUG
SG_ PAPPS: 16|16@1+ (1,0) [0|65535] "" DEBUG

BO_ 320 ANGLE_DBUG: 8 FSM
SG_ PAPPS_ANGLE: 0|32@1+ (1,0) [-180|180] "deg" DEBUG
SG_ PAPPS_RAW_ADC: 32|32@1+ (1,0) [0|180] "V" DEBUG

BO_ 400 PDM_NON_CRITICAL_ERRORS: 1 PDM
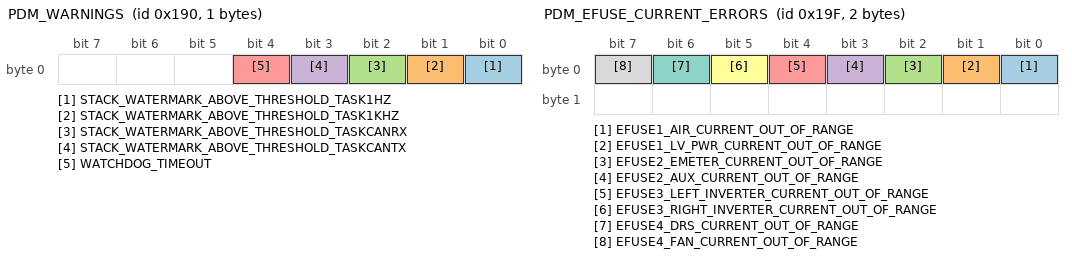
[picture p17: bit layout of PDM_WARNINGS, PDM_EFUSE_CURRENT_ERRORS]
BO_ 400 PDM_WARNINGS: 1 PDM
SG_ STACK_WATERMARK_ABOVE_THRESHOLD_TASK1HZ : 0|1@1+ (1,0) [0|1] "" DEBUG
SG_ STACK_WATERMARK_ABOVE_THRESHOLD_TASK1KHZ : 1|1@1+ (1,0) [0|1] "" DEBUG
SG_ STACK_WATERMARK_ABOVE_THRESHOLD_TASKCANRX : 2|1@1+ (1,0) [0|1] "" DEBUG
SG_ STACK_WATERMARK_ABOVE_THRESHOLD_TASKCANTX : 3|1@1+ (1,0) [0|1] "" DEBUG
SG_ WATCHDOG_TIMEOUT : 4|1@1+ (1,0) [0|1] "" DEBUG

BO_ 401 PDM_VITALS: 1 PDM
SG_ HEARTBEAT : 0|1@1+ (1,0) [0|1] "" BMS

BO_ 402 PDM_CAN_FIFO_OVERFLOW: 8 PDM
SG_ tx_overflow_count : 0|32@1+ (1,0) [0|4294967295] "" DEBUG
SG_ rx_overflow_count : 32|32@1+ (1,0) [0|4294967295] "" DEBUG

BO_ 403 PDM_STARTUP: 0 PDM

BO_ 405 PDM_MOTOR_SHUTDOWN_ERRORS: 8 PDM
SG_ DUMMY_MOTOR_SHUTDOWN : 0|1@1+ (1,0) [0|1] "" DCM

BO_ 412 PDM_WATCHDOG_TIMEOUT: 8 PDM
SG_ TASK_NAME : 0|64@1+ (1,0) [0|0] "" DEBUG

BO_ 414 PDM_AIR_SHUTDOWN_ERRORS: 8 PDM
SG_ DUMMY_AIR_SHUTDOWN : 0|1@1+ (1,0) [0|1] "" DCM

BO_ 415 PDM_EFUSE_CURRENT_ERRORS: 2 PDM
SG_ EFUSE1_AIR_CURRENT_OUT_OF_RANGE : 0|1@1+ (1,0) [0|1] "" DEBUG
SG_ EFUSE1_LV_PWR_CURRENT_OUT_OF_RANGE : 1|1@1+ (1,0) [0|1] "" DEBUG
SG_ EFUSE2_EMETER_CURRENT_OUT_OF_RANGE : 2|1@1+ (1,0) [0|1] "" DEBUG
SG_ EFUSE2_AUX_CURRENT_OUT_OF_RANGE : 3|1@1+ (1,0) [0|1] "" DEBUG
SG_ EFUSE3_LEFT_INVERTER_CURRENT_OUT_OF_RANGE : 4|1@1+ (1,0) [0|1] "" DEBUG
SG_ EFUSE3_RIGHT_INVERTER_CURRENT_OUT_OF_RANGE : 5|1@1+ (1,0) [0|1] "" DEBUG
SG_ EFUSE4_DRS_CURRENT_OUT_OF_RANGE : 6|1@1+ (1,0) [0|1] "" DEBUG
SG_ EFUSE4_FAN_CURRENT_OUT_OF_RANGE : 7|1@1+ (1,0) [0|1] "" DEBUG

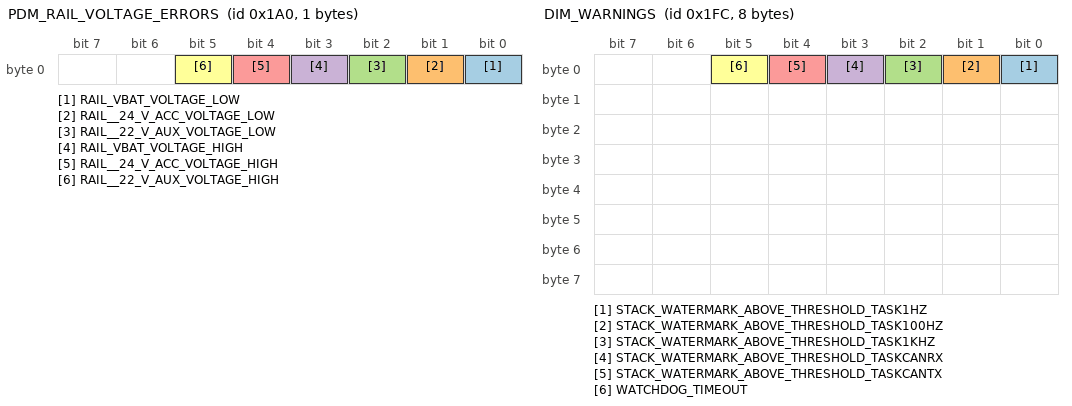
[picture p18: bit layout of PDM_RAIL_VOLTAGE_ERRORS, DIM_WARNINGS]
BO_ 416 PDM_RAIL_VOLTAGE_ERRORS: 1 PDM
SG_ RAIL_VBAT_VOLTAGE_LOW : 0|1@1+ (1,0) [0|1] "" DEBUG
SG_ RAIL__24_V_ACC_VOLTAGE_LOW : 1|1@1+ (1,0) [0|1] "" DEBUG
SG_ RAIL__22_V_AUX_VOLTAGE_LOW : 2|1@1+ (1,0) [0|1] "" DEBUG
SG_ RAIL_VBAT_VOLTAGE_HIGH : 3|1@1+ (1,0) [0|1] "" DEBUG
SG_ RAIL__24_V_ACC_VOLTAGE_HIGH : 4|1@1+ (1,0) [0|1] "" DEBUG
SG_ RAIL__22_V_AUX_VOLTAGE_HIGH : 5|1@1+ (1,0) [0|1] "" DEBUG

BO_ 417 PDM_EFUSE1_CURRENTS: 8 PDM
SG_ EFUSE1_AIR_CURRENT: 0|32@1+ (1,0) [-32767|32767] "mA" DEBUG
SG_ EFUSE1_LV_PWR_CURRENT: 32|32@1+ (1,0) [-32767|32767] "mA" DEBUG

BO_ 418 PDM_EFUSE2_CURRENTS: 8 PDM
SG_ EFUSE2_EMETER_CURRENT: 0|32@1+ (1,0) [-32767|32767] "mA" DEBUG
SG_ EFUSE2_AUX_CURRENT: 32|32@1+ (1,0) [-32767|32767] "mA" DEBUG

BO_ 419 PDM_EFUSE3_CURRENTS: 8 PDM
SG_ EFUSE3_LEFT_INVERTER_CURRENT: 0|32@1+ (1,0) [-32767|32767] "mA" DEBUG
SG_ EFUSE3_RIGHT_INVERTER_CURRENT: 32|32@1+ (1,0) [-32767|32767] "mA" DEBUG

BO_ 420 PDM_EFUSE4_CURRENTS: 8 PDM
SG_ EFUSE4_DRS_CURRENT: 0|32@1+ (1,0) [-32767|32767] "mA" DEBUG
SG_ EFUSE4_FAN_CURRENT: 32|32@1+ (1,0) [-32767|32767] "mA" DEBUG

BO_ 421 PDM_VBAT_VOLTAGE: 4 PDM
SG_ RAIL_VBAT_VOLTAGE: 0|32@1+ (1,0) [0|600] "V" DEBUG

BO_ 422 PDM__24_V_ACC_VOLTAGE: 4 PDM
SG_ RAIL__24_V_ACC_VOLTAGE: 0|32@1+ (1,0) [0|600] "V" DEBUG

BO_ 423 PDM__22_V_AUX_VOLTAGE: 4 PDM
SG_ RAIL__22_V_AUX_VOLTAGE: 0|32@1+ (1,0) [0|600] "V" DEBUG

BO_ 500 DIM_VITALS: 1 DIM
SG_ HEARTBEAT : 0|1@1+ (1,0) [0|1] "" FSM,DCM,PDM,BMS

BO_ 152 DIM_CAN_FIFO_OVERFLOW: 8 DIM
SG_ tx_overflow_count : 0|32@1+ (1,0) [0|4294967295] "" DEBUG
SG_ rx_overflow_count : 32|32@1+ (1,0) [0|4294967295] "" DEBUG

BO_ 502 DIM_STARTUP: 0 DIM

BO_ 503 DIM_STATE_MACHINE : 1 DIM
SG_ State : 0|8@1+ (1,0) [0|255] "" DEBUG

BO_ 504 DIM_WATCHDOG_TIMEOUT: 8 DIM
SG_ TASK_NAME : 0|64@1+ (1,0) [0|0] "" DEBUG

BO_ 508 DIM_WARNINGS: 8 DIM
SG_ STACK_WATERMARK_ABOVE_THRESHOLD_TASK1HZ : 0|1@1+ (1,0) [0|1] "" LOGGER
SG_ STACK_WATERMARK_ABOVE_THRESHOLD_TASK100HZ : 1|1@1+ (1,0) [0|1] "" LOGGER
SG_ STACK_WATERMARK_ABOVE_THRESHOLD_TASK1KHZ : 2|1@1+ (1,0) [0|1] "" LOGGER
SG_ STACK_WATERMARK_ABOVE_THRESHOLD_TASKCANRX : 3|1@1+ (1,0) [0|1] "" LOGGER
SG_ STACK_WATERMARK_ABOVE_THRESHOLD_TASKCANTX : 4|1@1+ (1,0) [0|1] "" LOGGER
SG_ WATCHDOG_TIMEOUT : 5|1@1+ (1,0) [0|1] "" LOGGER

BO_ 509 DIM_AIR_SHUTDOWN_ERRORS: 8 DIM
SG_ DUMMY_AIR_SHUTDOWN : 0|1@1+ (1,0) [0|1] "" DCM

BO_ 510 DIM_MOTOR_SHUTDOWN_ERRORS: 8 DIM
SG_ DUMMY_MOTOR_SHUTDOWN : 0|1@1+ (1,0) [0|1] "" DCM

BO_ 600 CAN_DEBUGGING_SIGNALS: 1 CAN_DBG
SG_ ENABLE_CELL_BALANCING : 0|1@1+ (1,0) [0|1] "" BMS
SG_ FORCE_DCM_TO_DRIVE_FROM_INIT : 1|1@1+ (1,0) [0|1] "" DCM

BO_ 700 GSM_STARTUP: 0 GSM

BO_ 701 GSM_VITALS: 1 GSM
SG_ HEARTBEAT : 0|1@1+ (1,0) [0|1] "" DEBUG

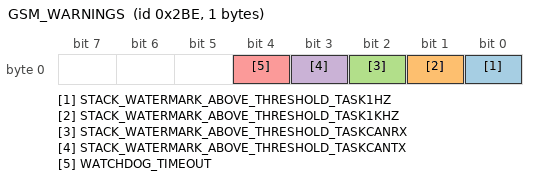
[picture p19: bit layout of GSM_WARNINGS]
BO_ 702 GSM_WARNINGS: 1 GSM
SG_ STACK_WATERMARK_ABOVE_THRESHOLD_TASK1HZ : 0|1@1+ (1,0) [0|1] "" DEBUG
SG_ STACK_WATERMARK_ABOVE_THRESHOLD_TASK1KHZ : 1|1@1+ (1,0) [0|1] "" DEBUG
SG_ STACK_WATERMARK_ABOVE_THRESHOLD_TASKCANRX : 2|1@1+ (1,0) [0|1] "" DEBUG
SG_ STACK_WATERMARK_ABOVE_THRESHOLD_TASKCANTX : 3|1@1+ (1,0) [0|1] "" DEBUG
SG_ WATCHDOG_TIMEOUT : 4|1@1+ (1,0) [0|1] "" DEBUG

BO_ 703 GSM_AIR_SHUTDOWN_ERRORS: 1 GSM
SG_ DUMMY_AIR_SHUTDOWN : 0|1@1+ (1,0) [0|1] "" DEBUG

BO_ 704 GSM_MOTOR_SHUTDOWN_ERRORS: 1 GSM
SG_ DUMMY_MOTOR_SHUTDOWN : 0|1@1+ (1,0) [0|1] "" DEBUG

BO_ 705 GSM_WATCHDOG_TIMEOUT : 8 GSM
SG_ TASK_NAME : 0|64@1+ (1,0) [0|0] "" DEBUG

BO_ 706 GSM_STATE_MACHINE : 1 GSM
SG_ STATE : 0|8@1+ (1,0) [0|255] "" DEBUG

BO_ 707 GSM_CAN_FIFO_OVERFLOW: 8 GSM
SG_ tx_overflow_count : 0|32@1+ (1,0) [0|4294967295] "" DEBUG
SG_ rx_overflow_count : 32|32@1+ (1,0) [0|4294967295] "" DEBUG

BA_DEF_  "BusType" STRING ;
BA_DEF_ BO_  "GenMsgCycleTime" INT 0 65535;
BA_DEF_ SG_  "GenSigStartValue" INT 0 2147483647;

BA_DEF_DEF_  "BusType" "CAN";
BA_DEF_DEF_  "GenMsgCycleTime" 0;
BA_DEF_DEF_  "GenSigStartValue" 0;

BA_ "GenSigStartValue" SG_ 32 Direction_Command_INVL 1;
BA_ "GenSigStartValue" SG_ 121 Start_Switch 1;

BA_ "GenMsgCycleTime" BO_ 0 100;
BA_ "GenMsgCycleTime" BO_ 1 100;
BA_ "GenMsgCycleTime" BO_ 2 100;
BA_ "GenMsgCycleTime" BO_ 5 10;
BA_ "GenMsgCycleTime" BO_ 6 10;
BA_ "GenMsgCycleTime" BO_ 7 10;
BA_ "GenMsgCycleTime" BO_ 9 100;
BA_ "GenMsgCycleTime" BO_ 10 10;
BA_ "GenMsgCycleTime" BO_ 11 10;
BA_ "GenMsgCycleTime" BO_ 12 10;
BA_ "GenMsgCycleTime" BO_ 32 10;

BA_ "GenMsgCycleTime" BO_ 50 100;
BA_ "GenMsgCycleTime" BO_ 51 100;
BA_ "GenMsgCycleTime" BO_ 52 100;
BA_ "GenMsgCycleTime" BO_ 55 10;
BA_ "GenMsgCycleTime" BO_ 56 10;
BA_ "GenMsgCycleTime" BO_ 57 10;
BA_ "GenMsgCycleTime" BO_ 59 100;
BA_ "GenMsgCycleTime" BO_ 60 10;
BA_ "GenMsgCycleTime" BO_ 61 10;
BA_ "GenMsgCycleTime" BO_ 62 10;
BA_ "GenMsgCycleTime" BO_ 82 10;

BA_ "GenMsgCycleTime" BO_ 90 10;

BA_ "GenMsgCycleTime" BO_ 100 100;
BA_ "GenMsgCycleTime" BO_ 101 5000;
BA_ "GenMsgCycleTime" BO_ 104 1000;
BA_ "GenMsgCycleTime" BO_ 105 1000;
BA_ "GenMsgCycleTime" BO_ 106 1000;
BA_ "GenMsgCycleTime" BO_ 107 10;
BA_ "GenMsgCycleTime" BO_ 108 1000;
BA_ "GenMsgCycleTime" BO_ 109 1000;
BA_ "GenMsgCycleTime" BO_ 110 1000;
BA_ "GenMsgCycleTime" BO_ 111 10;
BA_ "GenMsgCycleTime" BO_ 112 10;
BA_ "GenMsgCycleTime" BO_ 113 1000;
BA_ "GenMsgCycleTime" BO_ 114 100;
BA_ "GenMsgCycleTime" BO_ 115 100;
BA_ "GenMsgCycleTime" BO_ 116 100;
BA_ "GenMsgCycleTime" BO_ 117 100;
BA_ "GenMsgCycleTime" BO_ 118 100;
BA_ "GenMsgCycleTime" BO_ 120 100;
BA_ "GenMsgCycleTime" BO_ 13 10;
BA_ "GenMsgCycleTime" BO_ 151 100;
BA_ "GenMsgCycleTime" BO_ 200 100;
BA_ "GenMsgCycleTime" BO_ 201 5000;
BA_ "GenMsgCycleTime" BO_ 204 1000;
BA_ "GenMsgCycleTime" BO_ 205 100;
BA_ "GenMsgCycleTime" BO_ 206 100;
BA_ "GenMsgCycleTime" BO_ 207 1000;
BA_ "GenMsgCycleTime" BO_ 208 1000;
BA_ "GenMsgCycleTime" BO_ 212 10;
BA_ "GenMsgCycleTime" BO_ 300 1000;
BA_ "GenMsgCycleTime" BO_ 301 100;
BA_ "GenMsgCycleTime" BO_ 302 5000;
BA_ "GenMsgCycleTime" BO_ 305 100;
BA_ "GenMsgCycleTime" BO_ 307 1000;
BA_ "GenMsgCycleTime" BO_ 14 10;
BA_ "GenMsgCycleTime" BO_ 310 1000;
BA_ "GenMsgCycleTime" BO_ 315 1000;
BA_ "GenMsgCycleTime" BO_ 317 100;
BA_ "GenMsgCycleTime" BO_ 318 100;
BA_ "GenMsgCycleTime" BO_ 319 100;
BA_ "GenMsgCycleTime" BO_ 320 100;
BA_ "GenMsgCycleTime" BO_ 400 1000;
BA_ "GenMsgCycleTime" BO_ 401 1000;
BA_ "GenMsgCycleTime" BO_ 402 5000;
BA_ "GenMsgCycleTime" BO_ 405 5000;
BA_ "GenMsgCycleTime" BO_ 414 1000;
BA_ "GenMsgCycleTime" BO_ 415 100;
BA_ "GenMsgCycleTime" BO_ 500 100;
BA_ "GenMsgCycleTime" BO_ 152 10;
BA_ "GenMsgCycleTime" BO_ 503 1000;
BA_ "GenMsgCycleTime" BO_ 121 10;
BA_ "GenMsgCycleTime" BO_ 508 5000;
BA_ "GenMsgCycleTime" BO_ 509 1000;
BA_ "GenMsgCycleTime" BO_ 510 1000;
BA_ "GenMsgCycleTime" BO_ 600 1000;

BA_ "GenMsgCycleTime" BO_ 416 100;
BA_ "GenMsgCycleTime" BO_ 417 100;
BA_ "GenMsgCycleTime" BO_ 418 100;
BA_ "GenMsgCycleTime" BO_ 419 100;
BA_ "GenMsgCycleTime" BO_ 420 100;
BA_ "GenMsgCycleTime" BO_ 421 100;
BA_ "GenMsgCycleTime" BO_ 422 100;
BA_ "GenMsgCycleTime" BO_ 423 100;
BA_ "GenMsgCycleTime" BO_ 701 100;
BA_ "GenMsgCycleTime" BO_ 702 1000;
BA_ "GenMsgCycleTime" BO_ 703 1000;
BA_ "GenMsgCycleTime" BO_ 704 1000;
BA_ "GenMsgCycleTime" BO_ 706 1000;
BA_ "GenMsgCycleTime" BO_ 707 5000;

SIG_VALTYPE_ 90 FSM_Torque_Limit : 1;
SIG_VALTYPE_ 106 Duty_Cycle : 1;
SIG_VALTYPE_ 106 Frequency : 1;
SIG_VALTYPE_ 108 State_Of_Charge : 1;
SIG_VALTYPE_ 114 MIN_CELL_TEMPERATURE : 1;
SIG_VALTYPE_ 114 MAX_CELL_TEMPERATURE : 1;
SIG_VALTYPE_ 115 MIN_CELL_VOLTAGE: 1;
SIG_VALTYPE_ 115 MAX_CELL_VOLTAGE: 1;
SIG_VALTYPE_ 117 TS_VOLTAGE: 1;
SIG_VALTYPE_ 117 TS_CURRENT: 1;
SIG_VALTYPE_ 118 PACK_VOLTAGE: 1;
SIG_VALTYPE_ 120 AVAILABLE_POWER: 1;
SIG_VALTYPE_ 206 Torque_Request : 1;
SIG_VALTYPE_ 307 FLOW_RATE : 1;
SIG_VALTYPE_ 14 Brake_Pressure: 1;
SIG_VALTYPE_ 13 Mapped_Pedal_Percentage : 1;
SIG_VALTYPE_ 151 Papps_Mapped_Pedal_Percentage : 1;
SIG_VALTYPE_ 151 Sapps_Mapped_Pedal_Percentage : 1;
SIG_VALTYPE_ 317 Left_Wheel_Speed: 1;
SIG_VALTYPE_ 317 Right_Wheel_Speed: 1;
SIG_VALTYPE_ 318 Steering_Angle: 1;
SIG_VALTYPE_ 320 PAPPS_RAW_ADC : 1;
SIG_VALTYPE_ 320 PAPPS_ANGLE : 1;
SIG_VALTYPE_ 417 EFUSE1_AIR_CURRENT : 1;
SIG_VALTYPE_ 417 EFUSE1_LV_PWR_CURRENT : 1;
SIG_VALTYPE_ 418 EFUSE2_EMETER_CURRENT : 1;
SIG_VALTYPE_ 418 EFUSE2_AUX_CURRENT : 1;
SIG_VALTYPE_ 419 EFUSE3_LEFT_INVERTER_CURRENT : 1;
SIG_VALTYPE_ 419 EFUSE3_RIGHT_INVERTER_CURRENT : 1;
SIG_VALTYPE_ 420 EFUSE4_DRS_CURRENT : 1;
SIG_VALTYPE_ 420 EFUSE4_FAN_CURRENT : 1;
SIG_VALTYPE_ 421 RAIL_VBAT_VOLTAGE : 1;
SIG_VALTYPE_ 422 RAIL__24_V_ACC_VOLTAGE : 1;
SIG_VALTYPE_ 423 RAIL__22_V_AUX_VOLTAGE : 1;

VAL_ 10 D2_Inverter_State_INVL 0 "Power up" 1 "Stop" 2 "Open Loop" 3 "Closed Loop" 4 "Internal State" 5 "Internal State" 6 "Internal State" 7 "Internal State" 8 "Idle Run" 9 "Idle Stop" 10 "Internal State" 11 "Intern State" 12 "Internal State";
VAL_ 10 D1_VSM_State_INVL 0 "VSM Start State" 1 "Pre-Charge Init state" 2 "pre-charge active state" 3 "pre-charge complete state" 4 "VSM wait state" 5 "VSM ready state" 6 "Motor Running State" 7 "blink fault code state" 14 "Shutdown state for Key Switch Mode 1" 15 "Reset the inverter";
VAL_ 32 Inverter_Enable_INVL 0 "OFF" 1 "ON";
VAL_ 32 Direction_Command_INVL 0 "CW" 1 "CCW";
VAL_ 32 Inverter_Discharge_INVL 0 "Discharge Disable" 1 "Discharge Enable (if EEPROM parameter is set)";

VAL_ 60 D2_Inverter_State_INVR 0 "Power up" 1 "Stop" 2 "Open Loop" 3 "Closed Loop" 4 "Internal State" 5 "Internal State" 6 "Internal State" 7 "Internal State" 8 "Idle Run" 9 "Idle Stop" 10 "Internal State" 11 "Intern State" 12 "Internal State";
VAL_ 60 D1_VSM_State_INVR 0 "VSM Start State" 1 "Pre-Charge Init state" 2 "pre-charge active state" 3 "pre-charge complete state" 4 "VSM wait state" 5 "VSM ready state" 6 "Motor Running State" 7 "blink fault code state" 14 "Shutdown state for Key Switch Mode 1" 15 "Reset the inverter";
VAL_ 82 Inverter_Enable_INVR 0 "OFF" 1 "ON";
VAL_ 82 Direction_Command_INVR 0 "CW" 1 "CCW";
VAL_ 82 Inverter_Discharge_INVR 0 "Discharge Disable" 1 "Discharge Enable (if EEPROM parameter is set)";

VAL_ 105 Condition 0 "IMD_SHORT_CIRCUIT" 1 "IMD_NORMAL" 2 "IMD_UNDERVOLTAGE_DETECTED" 3 "IMD_SST" 4 "IMD_DEVICE_ERROR" 5 "IMD_EARTH_FAULT" 6 "IMD_INVALID";
VAL_ 105 OK_HS 0 "NO FAULT" 1 "FAULT";
VAL_ 107 State 0 "INIT" 1 "AIR_OPEN" 2 "PRE_CHARGE" 3 "CHARGE" 4 "DRIVE" 5 "FAULT";
VAL_ 109 CHARGER_DISCONNECTED_IN_CHARGE_STATE  0 "OK" 1 "FAULT";
VAL_ 109 CELL_UNDERVOLTAGE_FAULT 0 "OK" 1 "FAULT";
VAL_ 109 CELL_OVERVOLTAGE_FAULT 0 "OK" 1 "FAULT";
VAL_ 109 HAS_PEC_FAULT 0 "OK" 1 "FAULT";
VAL_ 109 CELL_UNDERTEMP_FAULT 0 "OK" 1 "FAULT";
VAL_ 109 CELL_OVERTEMP_FAULT 0 "OK" 1 "FAULT";
VAL_ 109 CHARGER_FAULT_DETECTED 0 "OK" 1 "FAULT";
VAL_ 109 HAS_REACHED_MAX_V 0 "OK" 1 "FAULT";
VAL_ 109 CHARGING_EXT_SHUTDOWN_OCCURRED 0 "OK" 1 "FAULT";
VAL_ 109 TS_OVERCURRENT_FAULT 0 "OK" 1 "FAULT";
VAL_ 109 PRECHARGE_FAULT 0 "OK" 1 "FAULT";
VAL_ 110 IS_CHARGING_COMPLETE 0 "FALSE" 1 "TRUE";
VAL_ 112 AIR_POSITIVE 0 "OPEN" 1 "CLOSED";
VAL_ 112 AIR_NEGATIVE 0 "OPEN" 1 "CLOSED";
VAL_ 204 ACCELERATION_X_OUT_OF_RANGE 0 "OK" 1 "UNDERFLOW" 2 "OVERFLOW";
VAL_ 204 ACCELERATION_Y_OUT_OF_RANGE 0 "OK" 1 "UNDERFLOW" 2 "OVERFLOW";
VAL_ 204 ACCELERATION_Z_OUT_OF_RANGE 0 "OK" 1 "UNDERFLOW" 2 "OVERFLOW";
VAL_ 205 State 0 "INIT" 1 "DRIVE" 2 "FAULT";
VAL_ 207 MISSING_HEARTBEAT 0 "FALSE" 1 "TRUE";
VAL_ 212 Right_Inverter_Switch 0 "OFF" 1 "ON";
VAL_ 212 Left_Inverter_Switch 0 "OFF" 1 "ON";
VAL_ 300 LEFT_WHEEL_SPEED_OUT_OF_RANGE 0 "OK" 1 "UNDERFLOW" 2 "OVERFLOW";
VAL_ 300 RIGHT_WHEEL_SPEED_OUT_OF_RANGE 0 "OK" 1 "UNDERFLOW" 2 "OVERFLOW";
VAL_ 300 FLOW_RATE_OUT_OF_RANGE 0 "OK" 1 "UNDERFLOW" 2 "OVERFLOW";
VAL_ 300 STEERING_ANGLE_OUT_OF_RANGE 0 "OK" 1 "UNDERFLOW" 2 "OVERFLOW";
VAL_ 300 BRAKE_PRESSURE508_OUT_OF_RANGE 0 "OK" 1 "UNDERFLOW" 2 "OVERFLOW";
VAL_ 300 BRAKE_PRESSURE_OPEN_SC 0 "FALSE" 1 "TRUE";
VAL_ 300 BRAKE_PRESSURE_OPEN_OC 0 "FALSE" 1 "TRUE";

VAL_ 415 EFUSE1_AIR_CURRENT_OUT_OF_RANGE 0 "FALSE" 1 "TRUE";
VAL_ 415 EFUSE1_LV_PWR_CURRENT_OUT_OF_RANGE 0 "FALSE" 1 "TRUE";
VAL_ 415 EFUSE2_EMETER_CURRENT_OUT_OF_RANGE 0 "FALSE" 1 "TRUE";
VAL_ 415 EFUSE2_AUX_CURRENT_OUT_OF_RANGE 0 "FALSE" 1 "TRUE";
VAL_ 415 EFUSE3_LEFT_INVERTER_CURRENT_OUT_OF_RANGE 0 "FALSE" 1 "TRUE";
VAL_ 415 EFUSE3_RIGHT_INVERTER_CURRENT_OUT_OF_RANGE 0 "FALSE" 1 "TRUE";
VAL_ 415 EFUSE4_DRS_CURRENT_OUT_OF_RANGE 0 "FALSE" 1 "TRUE";
VAL_ 415 EFUSE4_FAN_CURRENT_OUT_OF_RANGE 0 "FALSE" 1 "TRUE";
VAL_ 416 RAIL_VBAT_VOLTAGE_LOW  0 "FALSE" 1 "TRUE";
VAL_ 416 RAIL__24_V_ACC_VOLTAGE_LOW 0 "FALSE" 1 "TRUE";
VAL_ 416 RAIL__22_V_AUX_VOLTAGE_LOW 0 "FALSE" 1 "TRUE";
VAL_ 416 RAIL_VBAT_VOLTAGE_HIGH  0 "FALSE" 1 "TRUE";
VAL_ 416 RAIL__24_V_ACC_VOLTAGE_HIGH 0 "FALSE" 1 "TRUE";
VAL_ 416 RAIL__22_V_AUX_VOLTAGE_HIGH 0 "FALSE" 1 "TRUE";

VAL_ 706 STATE 0 "DEFAULT";

VAL_ 305 State 0 "AIR_OPEN" 1 "AIR_CLOSED";
VAL_ 14 Brake_Is_Actuated 0 "FALSE" 1 "TRUE";
VAL_ 14 Pressure_Sensor_Is_Open_Or_Short_Circuit 0 "FALSE" 1 "TRUE";
VAL_ 315 APPS_Has_Disagreement 0 "FALSE" 1 "TRUE";
VAL_ 315 PAPPS_Alarm_Is_Active 0 "FALSE" 1 "TRUE";
VAL_ 315 SAPPS_Alarm_Is_Active 0 "FALSE" 1 "TRUE";
VAL_ 315 Plausibility_Check_Has_Failed 0 "FALSE" 1 "TRUE";
VAL_ 315 FLOW_METER_HAS_UNDERFLOW 0 "FALSE" 1 "TRUE";
VAL_ 315 Torque_Plausibility_Check_Failed 0 "FALSE" 1 "TRUE";
VAL_ 503 State 0 "DRIVE";
VAL_ 121 Start_Switch 0 "OFF" 1 "ON";
VAL_ 121 Traction_Control_Switch 0 "OFF" 1 "ON";
VAL_ 121 Torque_Vectoring_Switch  0 "OFF" 1 "ON";
